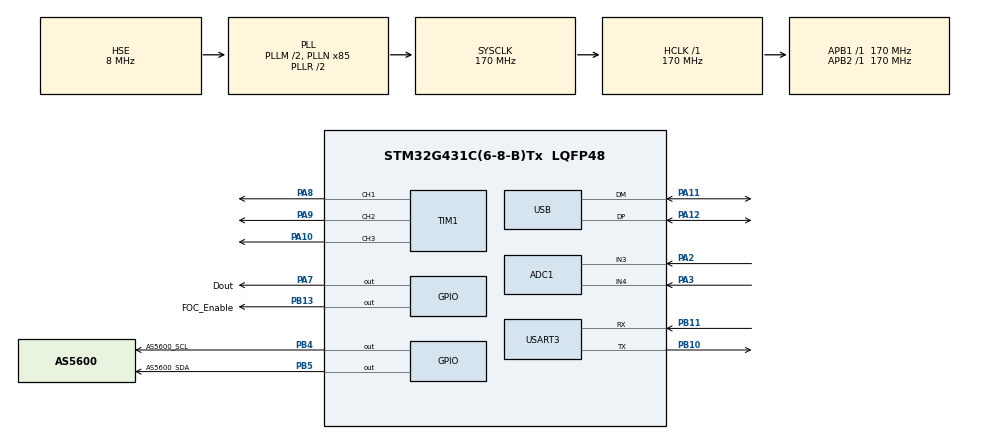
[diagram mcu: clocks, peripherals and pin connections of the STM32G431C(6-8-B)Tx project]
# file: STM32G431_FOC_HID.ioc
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ADC1.Channel-7\#ChannelRegularConversion=ADC_CHANNEL_3
ADC1.Channel-8\#ChannelRegularConversion=ADC_CHANNEL_4
ADC1.ContinuousConvMode=DISABLE
ADC1.DMAContinuousRequests=ENABLE
ADC1.NbrOfConversion=2
ADC1.NbrOfConversionFlag=1
ADC1.OffsetNumber-7\#ChannelRegularConversion=ADC_OFFSET_NONE
ADC1.OffsetNumber-8\#ChannelRegularConversion=ADC_OFFSET_NONE
ADC1.Rank-7\#ChannelRegularConversion=1
ADC1.Rank-8\#ChannelRegularConversion=2
ADC1.SamplingTime-7\#ChannelRegularConversion=ADC_SAMPLETIME_6CYCLES_5
ADC1.SamplingTime-8\#ChannelRegularConversion=ADC_SAMPLETIME_6CYCLES_5
ADC1.master=1
Dma.ADC1.0.Direction=DMA_PERIPH_TO_MEMORY
Dma.ADC1.0.EventEnable=DISABLE
Dma.ADC1.0.Instance=DMA1_Channel1
Dma.ADC1.0.MemDataAlignment=DMA_MDATAALIGN_WORD
Dma.ADC1.0.MemInc=DMA_MINC_ENABLE
Dma.ADC1.0.Mode=DMA_CIRCULAR
Dma.ADC1.0.PeriphDataAlignment=DMA_PDATAALIGN_WORD
Dma.ADC1.0.PeriphInc=DMA_PINC_DISABLE
Dma.ADC1.0.Polarity=HAL_DMAMUX_REQ_GEN_RISING
Dma.ADC1.0.Priority=DMA_PRIORITY_LOW
Dma.ADC1.0.RequestNumber=1
Dma.ADC1.0.SignalID=NONE
Dma.ADC1.0.SyncEnable=DISABLE
Dma.ADC1.0.SyncPolarity=HAL_DMAMUX_SYNC_NO_EVENT
Dma.ADC1.0.SyncRequestNumber=1
Dma.ADC1.0.SyncSignalID=NONE
Dma.Request0=ADC1
Mcu.Family=STM32G4
Mcu.Name=STM32G431C(6-8-B)Tx
Mcu.Package=LQFP48
Mcu.UserConstants=PWM_50KHZ_PSC,1-1;PWM_50KHZ_ARR,3400-1
NVIC.DMA1_Channel1_IRQn=true\:0\:0\:false\:false\:true\:false\:true\:true
NVIC.PriorityGroup=NVIC_PRIORITYGROUP_4
NVIC.TIM1_UP_TIM16_IRQn=true\:0\:0\:false\:false\:true\:true\:true\:true
NVIC.TIM2_IRQn=true\:2\:0\:true\:false\:true\:true\:true\:true
NVIC.TIM3_IRQn=true\:2\:0\:true\:false\:true\:true\:true\:true
NVIC.USB_LP_IRQn=true\:0\:0\:false\:false\:true\:false\:true\:true
PA10.Signal=S_TIM1_CH3
PA11.Mode=Device
PA11.Signal=USB_DM
PA12.Mode=Device
PA12.Signal=USB_DP
PA13.Mode=Serial_Wire
PA13.Signal=SYS_JTMS-SWDIO
PA14.Mode=Serial_Wire
PA14.Signal=SYS_JTCK-SWCLK
PA2.Mode=IN3-Single-Ended
PA2.Signal=ADC1_IN3
PA3.Mode=IN4-Single-Ended
PA3.Signal=ADC1_IN4
PA7.GPIO_Label=Dout
PA7.GPIO_Speed=GPIO_SPEED_FREQ_MEDIUM
PA7.PinState=GPIO_PIN_RESET
PA7.Signal=GPIO_Output
PA8.Signal=S_TIM1_CH1
PA9.Signal=S_TIM1_CH2
PB10.Mode=Asynchronous
PB10.Signal=USART3_TX
PB11.Mode=Asynchronous
PB11.Signal=USART3_RX
PB13.GPIO_Label=FOC_Enable
PB13.GPIO_Speed=GPIO_SPEED_FREQ_MEDIUM
PB13.Signal=GPIO_Output
PB4.GPIO_Label=AS5600_SCL
PB4.GPIO_ModeDefaultOutputPP=GPIO_MODE_OUTPUT_OD
PB4.GPIO_PuPd=GPIO_PULLUP
PB4.GPIO_Speed=GPIO_SPEED_FREQ_LOW
PB4.PinState=GPIO_PIN_SET
PB4.Signal=GPIO_Output
PB5.GPIO_Label=AS5600_SDA
PB5.GPIO_ModeDefaultOutputPP=GPIO_MODE_OUTPUT_OD
PB5.GPIO_PuPd=GPIO_PULLUP
PB5.GPIO_Speed=GPIO_SPEED_FREQ_LOW
PB5.PinState=GPIO_PIN_SET
PB5.Signal=GPIO_Output
PF0-OSC_IN.Mode=HSE-External-Oscillator
PF0-OSC_IN.Signal=RCC_OSC_IN
PF1-OSC_OUT.Mode=HSE-External-Oscillator
PF1-OSC_OUT.Signal=RCC_OSC_OUT
ProjectManager.HeapSize=0x700
ProjectManager.StackSize=0x2000
ProjectManager.TargetToolchain=MDK-ARM V5.32
RCC.ADC12Freq_Value=170000000
RCC.AHBFreq_Value=170000000
RCC.APB1Freq_Value=170000000
RCC.APB1TimFreq_Value=170000000
RCC.APB2Freq_Value=170000000
RCC.APB2TimFreq_Value=170000000
RCC.CK48CLockSelection=RCC_USBCLKSOURCE_HSI48
RCC.CortexFreq_Value=170000000
RCC.EXTERNAL_CLOCK_VALUE=12288000
RCC.HCLKFreq_Value=170000000
RCC.HSE_VALUE=8000000
RCC.HSI48_VALUE=48000000
RCC.HSI_VALUE=16000000
RCC.LSE_VALUE=32768
RCC.PLLM=RCC_PLLM_DIV2
RCC.PLLN=85
RCC.PLLQ=RCC_PLLQ_DIV4
RCC.PLLSourceVirtual=RCC_PLLSOURCE_HSE
RCC.SYSCLKFreq_VALUE=170000000
RCC.SYSCLKSource=RCC_SYSCLKSOURCE_PLLCLK
RCC.USBFreq_Value=48000000
RCC.VCOOutputFreq_Value=340000000
SH.S_TIM1_CH1.0=TIM1_CH1,PWM Generation1 CH1
SH.S_TIM1_CH2.0=TIM1_CH2,PWM Generation2 CH2
SH.S_TIM1_CH3.0=TIM1_CH3,PWM Generation3 CH3
TIM1.AutoReloadPreload=TIM_AUTORELOAD_PRELOAD_ENABLE
TIM1.Channel-PWM\ Generation1\ CH1=TIM_CHANNEL_1
TIM1.Channel-PWM\ Generation2\ CH2=TIM_CHANNEL_2
TIM1.Channel-PWM\ Generation3\ CH3=TIM_CHANNEL_3
TIM1.CounterMode=TIM_COUNTERMODE_CENTERALIGNED1
TIM1.PeriodNoDither=PWM_50KHZ_ARR
TIM1.Prescaler=PWM_50KHZ_PSC
TIM2.AutoReloadPreload=TIM_AUTORELOAD_PRELOAD_ENABLE
TIM2.PeriodNoDither=PWM_50KHZ_ARR*2
TIM2.Prescaler=PWM_50KHZ_PSC
TIM3.PeriodNoDither=PWM_50KHZ_ARR
TIM3.Prescaler=PWM_50KHZ_PSC
USART3.VirtualMode-Asynchronous=VM_ASYNC
USB_DEVICE.CLASS_NAME_FS=CUSTOM_HID
USB_DEVICE.VirtualMode=CustomHid
USB_DEVICE.VirtualModeFS=Custom_Hid_FS
VP_SYS_VS_DBSignals.Mode=DisableDeadBatterySignals
VP_TIM2_VS_ClockSourceINT.Mode=Internal
VP_TIM3_VS_ClockSourceINT.Mode=Internal
VP_USB_DEVICE_VS_USB_DEVICE_CUSTOM_HID_FS.Mode=CUSTOM_HID_FS
board=custom

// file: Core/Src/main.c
/* USER CODE BEGIN Header */
/**
  ******************************************************************************
  * @file           : main.c
  * @brief          : Main program body
  ******************************************************************************
  * @attention
  *
  * Copyright (c) 2023 STMicroelectronics.
  * All rights reserved.
  *
  * This software is licensed under terms that can be found in the LICENSE file
  * in the root directory of this software component.
  * If no LICENSE file comes with this software, it is provided AS-IS.
  *
  ******************************************************************************
  */
/* USER CODE END Header */
#include "main.h"
#include "adc.h"
#include "dma.h"
#include "tim.h"
#include "usart.h"
#include "usb_device.h"
#include "gpio.h"

/* USER CODE BEGIN Includes */
//#include "usbd_cdc_if.h"
/* USER CODE END Includes */

/* USER CODE BEGIN PTD */
#include "common_inc.h"
/* USER CODE END PTD */

void SystemClock_Config(void);

int main(void)
{

  /* MCU Configuration--------------------------------------------------------*/

  /* Reset of all peripherals, Initializes the Flash interface and the Systick. */
  HAL_Init();

  /* Configure the system clock */
  SystemClock_Config();

  /* USER CODE BEGIN SysInit */
  GPIO_InitTypeDef GPIO_InitStruct = {0};
  __HAL_RCC_GPIOA_CLK_ENABLE();
  HAL_GPIO_WritePin(GPIOA, GPIO_PIN_12, GPIO_PIN_RESET);
  GPIO_InitStruct.Pin = GPIO_PIN_12;
  GPIO_InitStruct.Mode = GPIO_MODE_OUTPUT_PP;
  GPIO_InitStruct.Pull = GPIO_NOPULL;
  GPIO_InitStruct.Speed = GPIO_SPEED_FREQ_MEDIUM;
  HAL_GPIO_Init(GPIOA, &GPIO_InitStruct);
  HAL_GPIO_WritePin(GPIOA, GPIO_PIN_12, GPIO_PIN_RESET);
  /* USER CODE END SysInit */

  /* Initialize all configured peripherals */
  MX_GPIO_Init();
  MX_DMA_Init();
  MX_USB_Device_Init();
  MX_ADC1_Init();
  MX_TIM1_Init();
  MX_TIM2_Init();
  MX_TIM3_Init();
  MX_USART3_UART_Init();
  /* USER CODE BEGIN 2 */
  HAL_Delay(1000);
  AppMain();
  /* USER CODE END 2 */

  /* Infinite loop */
  while (1)
  {

  }
}

void SystemClock_Config(void)
{
  RCC_OscInitTypeDef RCC_OscInitStruct = {0};
  RCC_ClkInitTypeDef RCC_ClkInitStruct = {0};

  /** Configure the main internal regulator output voltage
  */
  HAL_PWREx_ControlVoltageScaling(PWR_REGULATOR_VOLTAGE_SCALE1_BOOST);

  /** Initializes the RCC Oscillators according to the specified parameters
  * in the RCC_OscInitTypeDef structure.
  */
  RCC_OscInitStruct.OscillatorType = RCC_OSCILLATORTYPE_HSI48|RCC_OSCILLATORTYPE_HSE;
  RCC_OscInitStruct.HSEState = RCC_HSE_ON;
  RCC_OscInitStruct.HSI48State = RCC_HSI48_ON;
  RCC_OscInitStruct.PLL.PLLState = RCC_PLL_ON;
  RCC_OscInitStruct.PLL.PLLSource = RCC_PLLSOURCE_HSE;
  RCC_OscInitStruct.PLL.PLLM = RCC_PLLM_DIV2;
  RCC_OscInitStruct.PLL.PLLN = 85;
  RCC_OscInitStruct.PLL.PLLP = RCC_PLLP_DIV2;
  RCC_OscInitStruct.PLL.PLLQ = RCC_PLLQ_DIV4;
  RCC_OscInitStruct.PLL.PLLR = RCC_PLLR_DIV2;
  if (HAL_RCC_OscConfig(&RCC_OscInitStruct) != HAL_OK)
  {
    Error_Handler();
  }

  /** Initializes the CPU, AHB and APB buses clocks
  */
  RCC_ClkInitStruct.ClockType = RCC_CLOCKTYPE_HCLK|RCC_CLOCKTYPE_SYSCLK
                              |RCC_CLOCKTYPE_PCLK1|RCC_CLOCKTYPE_PCLK2;
  RCC_ClkInitStruct.SYSCLKSource = RCC_SYSCLKSOURCE_PLLCLK;
  RCC_ClkInitStruct.AHBCLKDivider = RCC_SYSCLK_DIV1;
  RCC_ClkInitStruct.APB1CLKDivider = RCC_HCLK_DIV1;
  RCC_ClkInitStruct.APB2CLKDivider = RCC_HCLK_DIV1;

  if (HAL_RCC_ClockConfig(&RCC_ClkInitStruct, FLASH_LATENCY_4) != HAL_OK)
  {
    Error_Handler();
  }
}

void Error_Handler(void)
{
  __disable_irq();
  while (1)
  {
  }
}
